# PIC32MX110F016D device description
Architecture: MIPS; Family: PIC32MX; Series: PIC32MX
Registers are 32-bit, read-write, no defined reset value unless marked. A register's access mark holds for its fields unless they carry their own. Offsets are from the block's base; [hi:lo] are bit positions; 'fields as' and 'values as' point back to an identical list.

## NVM
Instances: NVM 0x1f80f400 in periph1
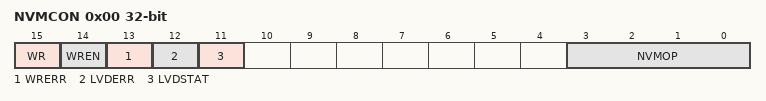
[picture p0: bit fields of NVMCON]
0x00 NVMCON — Programming Control Register
  [15] WR — Write Control bit
    1=Initiate a Flash operation. Hardware clears this bit when the operation completes; 0=Flash operation complete or inactive
  [14] WREN — Write Enable bit
    1=Enable writes to WR bit and enables LVD circuit; 0=Disable writes to WR bit and disables LVD circuit
  [13] WRERR — Write Error bit
    1=Program or erase sequence did not complete successfully; 0=Program or erase sequence completed normally
  [12] LVDERR — Low-Voltage Detect Error bit (LVD circuit must be enabled)
    1=Low-voltage detected (possible data corruption if WRERR is set); 0=Voltage level is acceptable for programming
  [11] LVDSTAT — Low-Voltage Detect Status bit (LVD circuit must be enabled)
    1=Low-voltage event active; 0=Low-voltage event NOT active
  [3:0] NVMOP — NVM Operation bits
    6=No operation; 5=Program Flash (PFM) erase operation: erases PFM if all pages are not write-protected; 4=Page erase operation: erases page selected by NVMADDR if it is not write-protected; 3=Row program operation: programs row selected by NVMADDR if it is not write-protected; 2=No operation; 1=Word program operation: programs word selected by NVMADDR if it is not write-protected; 0=No operation
0x10 NVMKEY wo — Programming Unlock Register
0x20 NVMADDR — Flash Address Register
0x30 NVMDATA
0x40 NVMSRCADDR — Source Data Address Register

## OCMP
Instances: OCMP 0x1f803000 in periph0
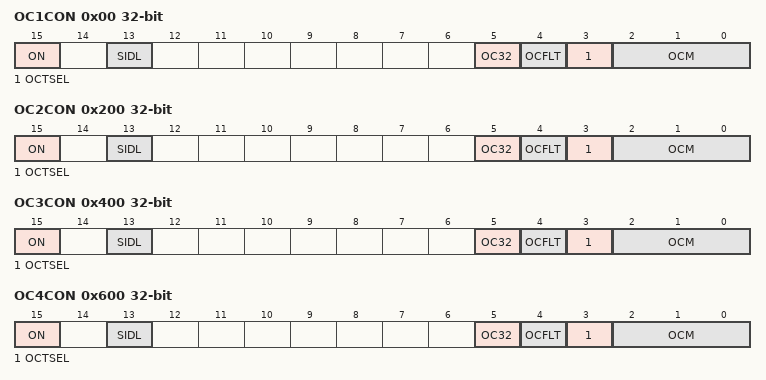
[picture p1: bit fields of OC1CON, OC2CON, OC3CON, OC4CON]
0x00 OC1CON — Output Compare 'x' Control Register
  [15] ON — Output Compare Peripheral On bit
    1=Output Compare peripheral is enabled; 0=Output Compare peripheral is disabled
  [13] SIDL — Stop in Idle Mode bit
    1=Discontinue operation when CPU enters Idle mode; 0=Continue operation in Idle mode
  [5] OC32 — 32-bit Compare Mode bit
    1=OCxR(31-0) and/or OCxRS(31-0) are used for comparisions to the 32-bit timer source; 0=OCxR(15-0) and OCxRS(15-0) are used for comparisons to the 16-bit timer source
  [4] OCFLT — PWM Fault Condition Status bit
    1=PWM Fault condition has occurred (cleared in HW only); 0=No PWM Fault condition has occurred
  [3] OCTSEL — Output Compare Timer Select bit
    1=Timer3 is the clock source for this Output Compare module; 0=Timer2 is the clock source for this Output Compare module
  [2:0] OCM — Output Compare Mode Select bits
    7=PWM mode on OCx; Fault pin enabled; 6=PWM mode on OCx; Fault pin disabled; 5=Initialize OCx pin low; generate continious output pulses on OCx pin; 4=Initialize OCx pin low: generate single output pulse on OCx pin; 3=Compare event toggles OCx pin; 2=Initialize OCx pin high; compare event forces OCx pin low; 1=Initialize OCx pin low; compare event forces OCx pin high; 0=Output compare peripheral is disabled but continues to draw current
0x10 OC1R
0x20 OC1RS
0x200 OC2CON — Output Compare 'x' Control Register
  fields as OC1CON
0x210 OC2R
0x220 OC2RS
0x400 OC3CON — Output Compare 'x' Control Register
  fields as OC1CON
0x410 OC3R
0x420 OC3RS
0x600 OC4CON — Output Compare 'x' Control Register
  fields as OC1CON
0x610 OC4R
0x620 OC4RS
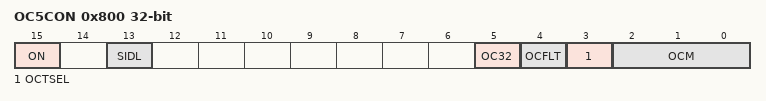
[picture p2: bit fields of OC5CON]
0x800 OC5CON — Output Compare 'x' Control Register
  fields as OC1CON
0x810 OC5R
0x820 OC5RS

## RCON
Instances: RCON 0x1f80f600 in periph1
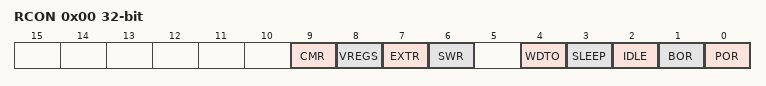
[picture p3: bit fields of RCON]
0x00 RCON — Reset Control Register
  [9] CMR — Configuration Mismatch Reset Flag bit
    1=Configuration mismatch Reset has occurred; 0=Configuration mismatch Reset has not occurred
  [8] VREGS — Voltage Regulator Standby Enable bit
    1=Regulator is enabled and is on during Sleep mode; 0=Regulator is set to standby tracking mode
  [7] EXTR — External Reset (MCLR) Pin Flag bit
    1=Master Clear (pin) Reset has occurred; 0=Master Clear (pin) Reset has not occurred
  [6] SWR — Software Reset Flag bit
    1=Software Reset was executed; 0=Software Reset as not executed
  [4] WDTO — Watchdog Timer Time-out Flag bit
    1=WDT Time-out has occurred; 0=WDT Time-out has not occurred
  [3] SLEEP — Wake From Sleep Flag bit
    1=Device was in Sleep mode; 0=Device was not in Sleep mode
  [2] IDLE — Wake From Idle Flag bit
    1=Device was in Idle mode; 0=Device was not in Idle mode
  [1] BOR — Brown-out Reset Flag bit
    1=Brown-out Reset has occurred; 0=Brown-out Reset has not occurred
  [0] POR — Power-on Reset Flag bit
    1=Power-on Reset has occurred; 0=Power-on Reset has not occurred
0x10 RSWRST — Software Reset Register
  [0] SWRST — Software Reset Trigger bit
    1=Enable Software Reset event; 0=No effect

## Notices in the file
Copyright (c) 2019 Microchip Technology Inc.
SPDX-License-Identifier: Apache-2.0
Licensed under the Apache License, Version 2.0 (the "License");
you may not use this file except in compliance with the License.
You may obtain a copy of the License at
http://www.apache.org/licenses/LICENSE-2.0
Unless required by applicable law or agreed to in writing, software
distributed under the License is distributed on an "AS IS" BASIS,
WITHOUT WARRANTIES OR CONDITIONS OF ANY KIND, either express or implied.
See the License for the specific language governing permissions and
limitations under the License.
